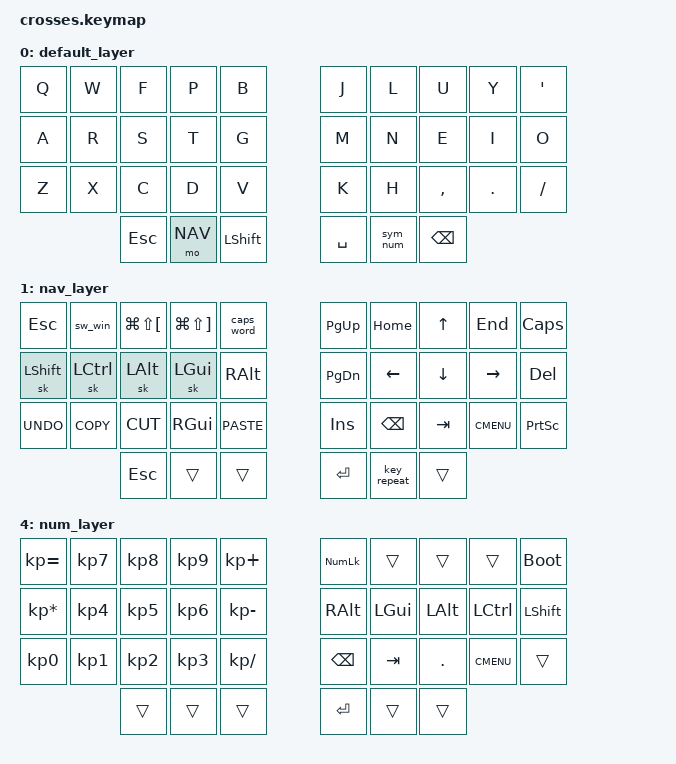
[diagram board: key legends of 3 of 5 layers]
#include <behaviors.dtsi>
#include <dt-bindings/zmk/keys.h>
#include <dt-bindings/zmk/bt.h>
#include <dt-bindings/zmk/rgb.h>
#include <dt-bindings/zmk/outputs.h>
#include <dt-bindings/zmk/pointing.h>

#define DEF 0
#define NAV 1
#define SYM 2
#define FUN 3
#define NUM 4

/* Configure sticky keys (one-shot mods) */
&sk {
    release-after-ms = <30000>;
    quick-release;
    ignore-modifiers;
};

/ {
    behaviors {
        /* Option A: Press SYM thumb key while Shift is held to activate NUM */
        sym_num: sym_num {
            compatible = "zmk,behavior-mod-morph";
            #binding-cells = <0>;
            bindings = <&mo SYM>, <&mo NUM>;
            mods = <(MOD_LSFT | MOD_RSFT)>;
        };

        /* Single-key window switcher: hold GUI, tap Tab, release GUI */
        sw_win: sw_win {
            label = "SW_WIN";
            compatible = "zmk,behavior-macro";
            #binding-cells = <0>;
            bindings
                = <&macro_press &kp LGUI>
                , <&macro_tap &kp TAB>
                , <&macro_pause_for_release>
                , <&macro_release &kp LGUI>
                ;
        };
    };

    conditional_layers {
        compatible = "zmk,conditional-layers";
        tri_layer {
            if-layers = <NAV SYM>;
            then-layer = <FUN>;
        };
    };

    keymap {
        compatible = "zmk,keymap";

        default_layer {
            bindings = <
                &kp Q       &kp W       &kp F       &kp P       &kp B       &kp J       &kp L       &kp U       &kp Y       &kp SQT
                &kp A       &kp R       &kp S       &kp T       &kp G       &kp M       &kp N       &kp E       &kp I       &kp O
                &kp Z       &kp X       &kp C       &kp D       &kp V       &kp K       &kp H       &kp COMMA   &kp DOT     &kp FSLH
                                        &kp ESC     &mo NAV     &kp LSHFT   &kp SPACE       &sym_num        &kp BSPC
            >;
        };

        nav_layer {
            bindings = <
                &kp ESC     &sw_win     &kp LG(LS(LBKT)) &kp LG(LS(RBKT)) &caps_word  &kp PG_UP   &kp HOME    &kp UP      &kp END     &kp CAPSLOCK
                &sk LSHIFT  &sk LCTRL   &sk LALT    &sk LGUI    &kp RALT    &kp PG_DN   &kp LEFT    &kp DOWN    &kp RIGHT   &kp DEL
                &kp K_UNDO  &kp K_COPY  &kp K_CUT   &kp RGUI    &kp K_PASTE &kp INSERT  &kp BSPC    &kp TAB     &kp K_CMENU &kp PSCRN
                                        &kp ESC     &trans      &trans      &kp RET         &key_repeat     &trans
            >;
        };

        sym_layer {
            bindings = <
                &kp EXCL    &kp AT      &kp HASH    &kp DLLR    &kp PRCNT   &kp GRAVE   &kp EQUAL   &kp COLON   &kp SEMI    &kp PLUS
                &kp LSHIFT  &kp LCTRL   &kp LALT    &kp LGUI    &kp CARET   &kp MINUS   &kp LPAR    &kp LBRC    &kp LBKT    &kp ASTRK
                &kp LT      &kp PIPE    &kp BSLH    &kp GT      &kp AMPS    &kp UNDERSCORE  &trans          &trans      &kp RPAR    &kp RBRC    &kp RBKT    &kp TILDE
                                        &trans      &trans      &trans      &kp RET         &trans          &trans
            >;
        };

        fun_layer {
            bindings = <
                &kp C_PREV  &kp C_STOP  &kp C_PP    &kp C_NEXT  &kp C_BRI_UP &kp F12     &kp F7      &kp F8      &kp F9      &rgb_ug RGB_TOG
                &kp LSHIFT  &kp LCTRL   &kp LALT    &kp LGUI    &kp C_BRI_DN &kp F11     &kp F4      &kp F5      &kp F6      &trans
                &kp C_MUTE  &kp C_VOL_DN &kp LG(LS(C)) &kp C_VOL_UP &kp LG(LS(V)) &kp F10   &kp F1          &kp F2      &kp F3      &trans      &trans      &trans
                                        &trans      &trans      &trans      &kp RET         &trans          &trans
            >;
        };

        num_layer {
            bindings = <
                &kp KP_EQUAL &kp KP_N7  &kp KP_N8   &kp KP_N9   &kp KP_PLUS  &kp KP_NUMLOCK &trans   &trans      &trans      &bootloader
                &kp KP_MULTIPLY &kp KP_N4 &kp KP_N5 &kp KP_N6   &kp KP_MINUS &kp RALT    &kp LGUI    &kp LALT    &kp LCTRL   &kp LSHIFT
                &kp KP_N0   &kp KP_N1   &kp KP_N2   &kp KP_N3   &kp KP_DIVIDE &kp BSPC    &kp TAB     &kp DOT     &kp K_CMENU &trans
                                        &trans      &trans      &trans      &kp RET         &trans          &trans
            >;
        };
    };
};
